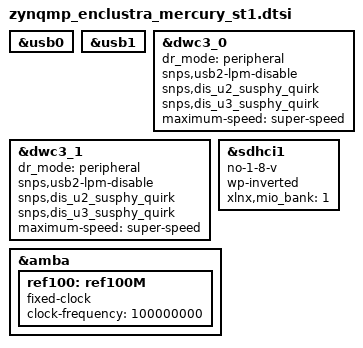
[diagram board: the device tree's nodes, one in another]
#include <dt-bindings/phy/phy.h>

&usb0 {
	status = "okay";
};

&usb1 {
	status = "okay";
};


&dwc3_0 {
	status = "okay";
	dr_mode = "peripheral";
	/delete-property/snps,usb3_lpm_capable;
  snps,usb2-lpm-disable;
  snps,dis_u2_susphy_quirk;
  snps,dis_u3_susphy_quirk;
	//phy-names = "usb3-phy";
	//phys = <&lane2 PHY_TYPE_USB3 0 2 100000000>;
  /delete-property/phy-names;
  /delete-property/phys;
	maximum-speed = "super-speed";
};

&dwc3_1 {
	status = "okay";
	dr_mode = "peripheral";
	/delete-property/snps,usb3_lpm_capable;
  snps,usb2-lpm-disable;
  snps,dis_u2_susphy_quirk;
  snps,dis_u3_susphy_quirk;
  /delete-property/phy-names;
  /delete-property/phys;
	//phy-names = "usb3-phy";
	//phys = <&lane3 PHY_TYPE_USB3 1 2 100000000>;
	maximum-speed = "super-speed";
	//maximum-speed = "super-speed";
};

/* SD1 with level shifter */
&sdhci1 {
	status = "okay";
	no-1-8-v;	/* for 1.0 silicon */
	wp-inverted;
	xlnx,mio_bank = <1>;
};

&amba {
	ref100: ref100M {
		compatible = "fixed-clock";
		#clock-cells = <0>;
		clock-frequency = <100000000>;
	};
};
